# R7KA8P1AD register map
Vendor: Renesas Electronics Corporation; Series: RA8; File version: 1.10.02
CPU: CM85 r0p2, little endian, MPU, FPU, VTOR, 4 interrupt priority bits, 96 interrupts
Registers are 32-bit, read-write, reset 0x0 unless marked. A register's access mark holds for its fields unless they carry their own. Offsets are from the block's base; [hi:lo] are bit positions; {n}, {i} and the like mark numbered series.

## PSCU — Peripheral Security Control Unit
Base 0x40204000
Same registers: PSCU_NS 0x50204000
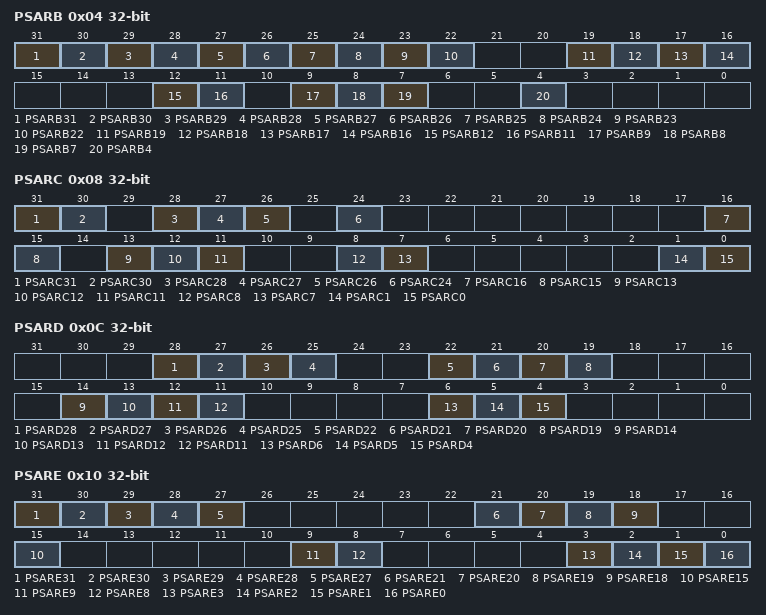
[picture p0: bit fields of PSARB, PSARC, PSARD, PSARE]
0x04 PSARB — Peripheral Security Attribution Register B
  [31] PSARB31 — Serial Communication Interface 0 Security Attribution
    0=Secure; 1=Non-secure
  [30] PSARB30 — Serial Communication Interface 1 Security Attribution
    0=Secure; 1=Non-secure
  [29] PSARB29 — Serial Communication Interface 2 Security Attribution
    0=Secure; 1=Non-secure
  [28] PSARB28 — Serial Communication Interface 3 Security Attribution
    0=Secure; 1=Non-secure
  [27] PSARB27 — Serial Communication Interface 4 Security Attribution
    0=Secure; 1=Non-secure
  [26] PSARB26 — Serial Communication Interface 5 Security Attribution
    0=Secure; 1=Non-secure
  [25] PSARB25 — Serial Communication Interface 6 Security Attribution
    0=Secure; 1=Non-secure
  [24] PSARB24 — Serial Communication Interface 7 Security Attribution
    0=Secure; 1=Non-secure
  [23] PSARB23 — Serial Communication Interface 8 Security Attribution
    0=Secure; 1=Non-secure
  [22] PSARB22 — Serial Communication Interface 9 Security Attribution
    0=Secure; 1=Non-secure
  [19] PSARB19 — Serial Peripheral Interface 0 Security Attribution
    0=Secure; 1=Non-secure
  [18] PSARB18 — Serial Peripheral Interface 1 Security Attribution
    0=Secure; 1=Non-secure
  [17] PSARB17 — Octa Memory Controller 1 Security Attribution
    0=Secure; 1=Non-secure
  [16] PSARB16 — Octa Memory Controller 0 Security Attribution
    0=Secure; 1=Non-secure
  [12] PSARB12 — Universal Serial Bus 2.0 HS Interface Security Attribution
    0=Secure; 1=Non-secure
  [11] PSARB11 — Universal Serial Bus 2.0 FS Interface 0 Security Attribution
    0=Secure; 1=Non-secure
  [9] PSARB9 — I2C Bus Interface 0 Security Attribution
    0=Secure; 1=Non-secure
  [8] PSARB8 — I2C Bus Interface 1 Security Attribution
    0=Secure; 1=Non-secure
  [7] PSARB7 — I2C Bus Interface 2 Security Attribution
    0=Secure; 1=NonSecure
  [4] PSARB4 — I3C Bus Interface Security Attribution
    0=Secure; 1=Non-secure
0x08 PSARC — Peripheral Security Attribution Register C
  [all] fields
    0=Secure; 1=Non-secure
  [31] PSARC31 — RSIP-E50D Security Attribution
  [30] PSARC30 — Layer 3 Ethernet Switch Module Security Attribution
  [28] PSARC28 — Ether-PHY clock Security Attribution
  [27] PSARC27 — Controller Area Network with Flexible Data-Rate 0 Security Attribution
  [26] PSARC26 — Controller Area Network with Flexible Data-Rate 1 Security Attribution
  [24] PSARC24 — Pulse Density Modulation Interface Security Attribution
  [16] PSARC16 — CEU Security Attribution
  [15] PSARC15 — Graphic (GLCDC, MIPI-DSI, MIPI-CSI, DRW) Security Attribution
  [13] PSARC13 — Data Operation Circuit Security Attribution
  [12] PSARC12 — Secure Digital Host IF 0 Security Attribution
  [11] PSARC11 — Secure Digital Host IF 1 Security Attribution
  [8] PSARC8 — Serial Sound Interface Enhanced (channel 0) Security Attribution
  [7] PSARC7 — Serial Sound Interface Enhanced (channel 1) Security Attribution
  [1] PSARC1 — Cyclic Redundancy Check Calculator Security Attribution
  [0] PSARC0 — Clock Frequency Accuracy Measurement Circuit Security Attribution.
0x0C PSARD — Peripheral Security Attribution Register D
  [all] fields
    0=Secure; 1=Non-secure
  [28] PSARD28 — High Speed Analog Comparator 0 Security Attribution
  [27] PSARD27 — High Speed analog Comparator 1 Security Attribution
  [26] PSARD26 — High speed analog Comparator 2 Security Attribution
  [25] PSARD25 — High speed analog Comparator 3 Security Attribution
  [22] PSARD22 — Temperature Sensor Security Attribution
  [21] PSARD21 — 16-Bit A/D Converter Security Attribution
  [20] PSARD20 — 12-Bit D/A Converter 0 Security Attribution
  [19] PSARD19 — 12-Bit D/A Converter 1 Security Attribution
  [14] PSARD14 — Port Output Enable for GPT Group 0 Security Attribution
  [13] PSARD13 — Port Output Enable for GPT Group 1 Security Attribution
  [12] PSARD12 — Port Output Enable for GPT Group 2 Security Attribution
  [11] PSARD11 — Port Output Enable for GPT Group 3 Security Attribution
  [6] PSARD6 — PWM Delay Generation Circuit Security Attribution
  [5] PSARD5 — Asynchronous General Purpose Timer 0 Security Attribution
  [4] PSARD4 — Asynchronous General Purpose Timer 1 Security Attribution
0x10 PSARE — Peripheral Security Attribution Register E
  [all] fields
    0=Secure; 1=Non-secure
  [31] PSARE31 — General PWM Timer Channel 0 Security Attribution
  [30] PSARE30 — General PWM Timer Channel 1 Security Attribution
  [29] PSARE29 — General PWM Timer Channel 2 Security Attribution
  [28] PSARE28 — General PWM Timer Channel 3 Security Attribution
  [27] PSARE27 — General PWM Timer Channel 4 Security Attribution
  [21] PSARE21 — General PWM Timer Channel 10 Security Attribution
  [20] PSARE20 — General PWM Timer Channel 11 Security Attribution
  [19] PSARE19 — General PWM Timer Channel 12 Security Attribution
  [18] PSARE18 — General PWM Timer Channel 13 Security Attribution
  [15] PSARE15 — GPT common Security Attribution
  [9] PSARE9 — ULPT0 Security Attribution
  [8] PSARE8 — ULPT1 Security Attribution
  [3] PSARE3 — Real Time Clock Security Attribution
  [2] PSARE2 — IWDT Security Attribution
  [1] PSARE1 — WDT0 Security Attribution
  [0] PSARE0 — WDT1 Security Attribution
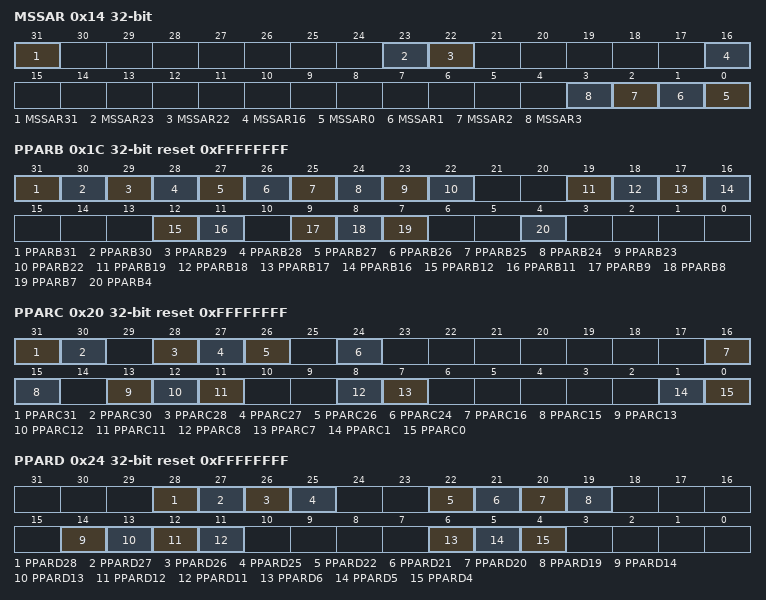
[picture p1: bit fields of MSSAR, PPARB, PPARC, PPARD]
0x14 MSSAR — Module Stop Security Attribution Register
  [all] fields
    0=Secure; 1=Non-secure
  [31] MSSAR31 — ELC Clock Stop Security Attribution
  [23] MSSAR23 — DMAC1/DTC1 Clock Stop Security Attribution
  [22] MSSAR22 — DMAC0/DTC0 Clock Stop Security Attribution
  [16] MSSAR16 — NPU Clock Stop Security Attribution
  [n] MSSAR{n} (n=0..3) — SRAM{n} Clock Stop Security Attribution
0x1C PPARB reset 0xFFFFFFFF — Peripheral Privilege Attribution Register B
  [all] fields
    0=Privileged; 1=Unprivileged
  [31] PPARB31 — Serial Communication Interface 0 Privilege Attribution
  [30] PPARB30 — Serial Communication Interface 1 Privilege Attribution
  [29] PPARB29 — Serial Communication Interface 2 Privilege Attribution
  [28] PPARB28 — Serial Communication Interface 3 Privilege Attribution
  [27] PPARB27 — Serial Communication Interface 4 Privilege Attribution
  [26] PPARB26 — Serial Communication Interface 5 Privilege Attribution
  [25] PPARB25 — Serial Communication Interface 6 Privilege Attribution
  [24] PPARB24 — Serial Communication Interface 7 Privilege Attribution
  [23] PPARB23 — Serial Communication Interface 8 Privilege Attribution
  [22] PPARB22 — Serial Communication Interface 9 Privilege Attribution
  [19] PPARB19 — Serial Peripheral Interface 0 Privilege Attribution
  [18] PPARB18 — Serial Peripheral Interface 1 Privilege Attribution
  [17] PPARB17 — Octa Memory Controller 1 Privilege Attribution
  [16] PPARB16 — Octa Memory Controller 0 Privilege Attribution
  [12] PPARB12 — Universal Serial Bus 2.0 HS Interface 0 Privilege Attribution
  [11] PPARB11 — Universal Serial Bus 2.0 FS Interface 0 Privilege Attribution
  [9] PPARB9 — I2C Bus Interface 0 Privilege Attribution
  [8] PPARB8 — I2C Bus Interface 1 Privilege Attribution
  [7] PPARB7 — I2C Bus Interface 2 Privilege Attribution
  [4] PPARB4 — I3C Bus Interface Privilege Attribution
0x20 PPARC reset 0xFFFFFFFF — Peripheral Privilege Attribution Register C
  [all] fields
    0=Privileged; 1=Unprivileged
  [31] PPARC31 — RSIP-E50D Privilege Attribution
  [30] PPARC30 — Layer 3 Ethernet Switch Module Privilege Attribution
  [28] PPARC28 — Ether-PHY clock Privilege Attribution
  [27] PPARC27 — Controller Area Network with Flexible Data-Rate 0 Privilege Attribution
  [26] PPARC26 — Controller Area Network with Flexible Data-Rate 1 Privilege Attribution
  [24] PPARC24 — Pulse Density Modulation Interface Privilege Attribution
  [16] PPARC16 — CEU Privilege Attribution
  [15] PPARC15 — Graphic (GLCDC, MIPI-DSI, MIPI-CSI, DRW) Privilege Attribution
  [13] PPARC13 — Data Operation Circuit Privilege Attribution
  [12] PPARC12 — Secure Digital Host IF 0 Privilege Attribution
  [11] PPARC11 — Secure Digital Host IF 1 Privilege Attribution
  [8] PPARC8 — Serial Sound Interface Enhanced (Channel 0) Privilege Attribution
  [7] PPARC7 — Serial Sound Interface Enhanced (Channel 1) Privilege Attribution
  [1] PPARC1 — Cyclic Redundancy Check Calculator Privilege Attribution
  [0] PPARC0 — Clock Frequency Accuracy Measurement Circuit Privilege Attribution
0x24 PPARD reset 0xFFFFFFFF — Peripheral Privilege Attribution Register D
  [all] fields
    0=Privileged; 1=Unprivileged
  [28] PPARD28 — High speed analog Comparator 0 Privilege Attribution
  [27] PPARD27 — High speed analog Comparator 1 Privilege Attribution
  [26] PPARD26 — High speed analog Comparator 2 Privilege Attribution
  [25] PPARD25 — High speed analog Comparator 3 Privilege Attribution
  [22] PPARD22 — Temperature Sensor Privilege Attribution
  [21] PPARD21 — 16-Bit A/D Converter Privilege Attribution
  [20] PPARD20 — 12-Bit D/A Converter 0 Privilege Attribution
  [19] PPARD19 — 12-Bit D/A Converter 1 Privilege Attribution
  [14] PPARD14 — Port Output Enable for GPT Group 0 Privilege Attribution
  [13] PPARD13 — Port Output Enable for GPT Group 1 Privilege Attribution
  [12] PPARD12 — Port Output Enable for GPT Group 2 Privilege Attribution
  [11] PPARD11 — Port Output Enable for GPT Group 3 Privilege Attribution
  [6] PPARD6 — PWM Delay Generation Circuit Privilege Attribution
  [5] PPARD5 — Asynchronous General Purpose Timer 0 Privilege Attribution
  [4] PPARD4 — Asynchronous General Purpose Timer 1 Privilege Attribution
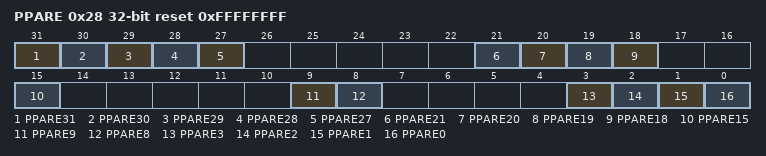
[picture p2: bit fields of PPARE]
0x28 PPARE reset 0xFFFFFFFF — Peripheral Privilege Attribution Register E
  [all] fields
    0=Privileged; 1=Unprivileged
  [31] PPARE31 — General PWM Timer Channel 0 Privilege Attribution
  [30] PPARE30 — General PWM Timer Channel 1 Privilege Attribution
  [29] PPARE29 — General PWM Timer Channel 2 Privilege Attribution
  [28] PPARE28 — General PWM Timer Channel 3 Privilege Attribution
  [27] PPARE27 — General PWM Timer Channel 4 Privilege Attribution
  [21] PPARE21 — General PWM Timer Channel 10 Privilege Attribution
  [20] PPARE20 — General PWM Timer Channel 11 Privilege Attribution
  [19] PPARE19 — General PWM Timer Channel 12 Privilege Attribution
  [18] PPARE18 — General PWM Timer Channel 13 Privilege Attribution
  [15] PPARE15 — GPT common Privilege Attribution
  [9] PPARE9 — ULPT0 Privilege Attribution
  [8] PPARE8 — ULPT1 Privilege Attribution
  [3] PPARE3 — Real Time Clock Privilege Attribution
  [2] PPARE2 — IWDT Privilege Attribution
  [1] PPARE1 — WDT0 Privilege Attribution
  [0] PPARE0 — WDT1 Privilege Attribution
0x2C MSPAR reset 0xFFFFFFFF — Module Stop Privilege Attribution Register
  [31] MSPAR31 — ELC Clock Stop Privilege Attribution
    0=Privileged; 1=Unprivileged
0x30 CMSAMON ro (reset mask 0xFF007FFF) — Code MRAM Security Attribution Monitor Register
  [23:15] CMS — Code MRAM Secure Area
0x38 DLMMON ro (reset mask 0xFFFFFFF0) — Device Lifecycle Management State Monitor Register
  [3:0] DLMMON — Device Lifecycle Management State Monitor
    4=OEM; 6=LCK_BOOT; 7=RMA_REQ; 8=RMA_ACK; 9=RMA_RET; other=Others (Reserved)
0x3C SFSAMON ro (reset mask 0xFF007FFF) — SiP Flash Security Attribution Monitor Register
  [23:15] SFS — SiP Flash Secure Area
